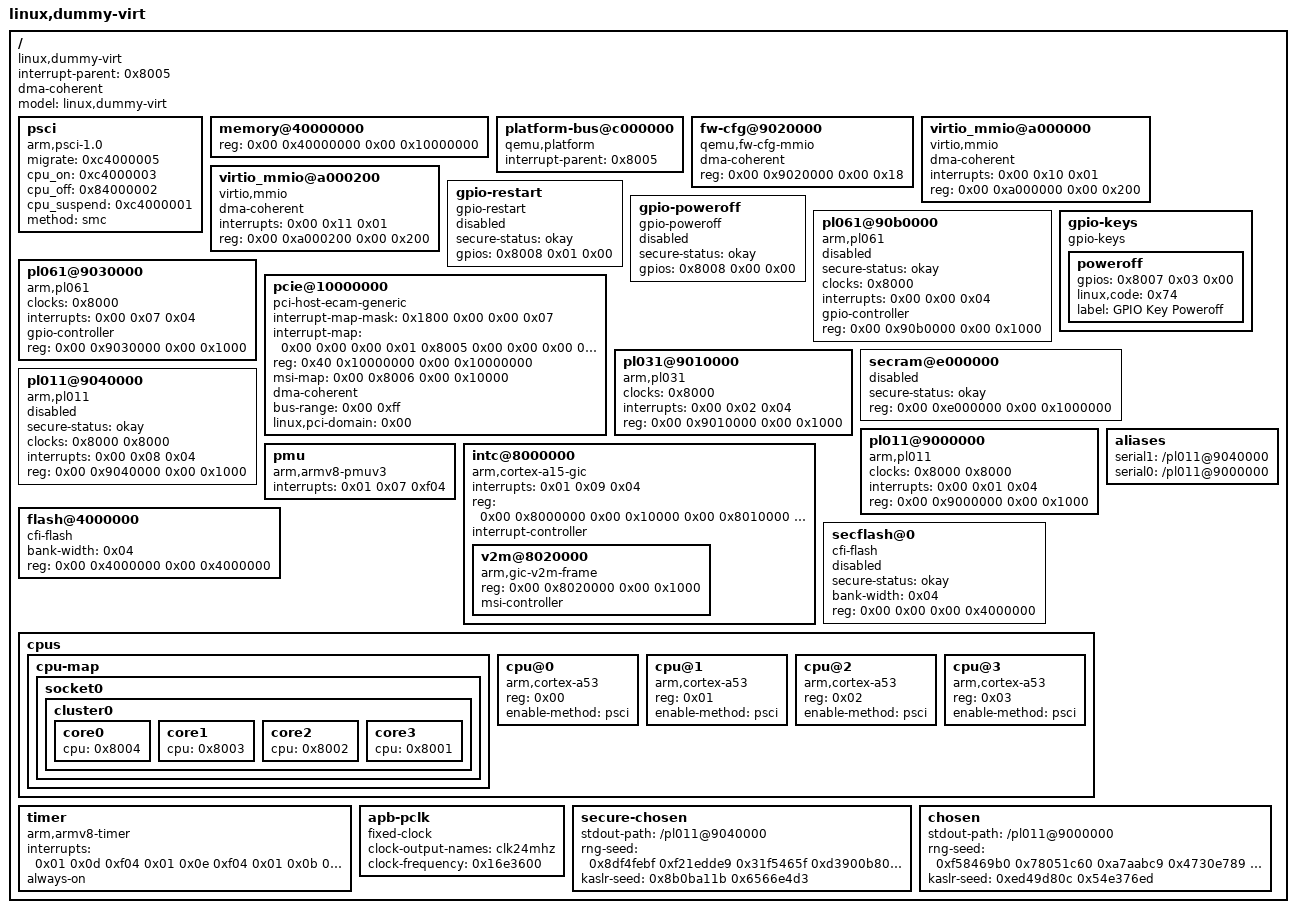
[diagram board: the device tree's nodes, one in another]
/dts-v1/;

/ {
	interrupt-parent = <0x8005>;
	dma-coherent;
	model = "linux,dummy-virt";
	#size-cells = <0x02>;
	#address-cells = <0x02>;
	compatible = "linux,dummy-virt";

	psci {
		migrate = <0xc4000005>;
		cpu_on = <0xc4000003>;
		cpu_off = <0x84000002>;
		cpu_suspend = <0xc4000001>;
		method = "smc";
		compatible = "arm,psci-1.0", "arm,psci-0.2", "arm,psci";
	};

	memory@40000000 {
		reg = <0x00 0x40000000 0x00 0x10000000>;
		device_type = "memory";
	};

    /* 没听懂 没用 */
	platform-bus@c000000 {
		interrupt-parent = <0x8005>;
		ranges = <0x00 0x00 0xc000000 0x2000000>;
		#address-cells = <0x01>;
		#size-cells = <0x01>;
		compatible = "qemu,platform", "simple-bus";
	};

    /* 估计那配置接口 只rtt */
	fw-cfg@9020000 {
		dma-coherent;
		reg = <0x00 0x9020000 0x00 0x18>;
		compatible = "qemu,fw-cfg-mmio";
	};

    /* 虚拟外设 */
	virtio_mmio@a000000 {
		dma-coherent;
		interrupts = <0x00 0x10 0x01>;
		reg = <0x00 0xa000000 0x00 0x200>;
		compatible = "virtio,mmio";
	};

	virtio_mmio@a000200 {
		dma-coherent;
		interrupts = <0x00 0x11 0x01>;
		reg = <0x00 0xa000200 0x00 0x200>;
		compatible = "virtio,mmio";
	};

    /* 系统重启 */
	gpio-restart {
		secure-status = "okay";
		status = "disabled";
		gpios = <0x8008 0x01 0x00>;
		compatible = "gpio-restart";
	};

    /* 系统关机 */
	gpio-poweroff {
		secure-status = "okay";
		status = "disabled";
		gpios = <0x8008 0x00 0x00>;
		compatible = "gpio-poweroff";
	};

    /* gpio控制器 只rtt */
	pl061@90b0000 {
		secure-status = "okay";
		status = "disabled";
		phandle = <0x8008>;
		clock-names = "apb_pclk";
		clocks = <0x8000>;
		interrupts = <0x00 0x00 0x04>;
		gpio-controller;
		#gpio-cells = <0x02>;
		compatible = "arm,pl061", "arm,primecell";
		reg = <0x00 0x90b0000 0x00 0x1000>;
	};


	gpio-keys {
		compatible = "gpio-keys";

		poweroff {
			gpios = <0x8007 0x03 0x00>;
			linux,code = <0x74>;
			label = "GPIO Key Poweroff";
		};
	};

	pl061@9030000 {
		phandle = <0x8007>;
		clock-names = "apb_pclk";
		clocks = <0x8000>;
		interrupts = <0x00 0x07 0x04>;
		gpio-controller;
		#gpio-cells = <0x02>;
		compatible = "arm,pl061", "arm,primecell";
		reg = <0x00 0x9030000 0x00 0x1000>;
	};

    /* 只rtt */
	pcie@10000000 {
		interrupt-map-mask = <0x1800 0x00 0x00 0x07>;
		interrupt-map = <0x00 0x00 0x00 0x01 0x8005 0x00 0x00 0x00 0x03 0x04 0x00 0x00 0x00 0x02 0x8005 0x00 0x00 0x00 0x04 0x04 0x00 0x00 0x00 0x03 0x8005 0x00 0x00 0x00 0x05 0x04 0x00 0x00 0x00 0x04 0x8005 0x00 0x00 0x00 0x06 0x04 0x800 0x00 0x00 0x01 0x8005 0x00 0x00 0x00 0x04 0x04 0x800 0x00 0x00 0x02 0x8005 0x00 0x00 0x00 0x05 0x04 0x800 0x00 0x00 0x03 0x8005 0x00 0x00 0x00 0x06 0x04 0x800 0x00 0x00 0x04 0x8005 0x00 0x00 0x00 0x03 0x04 0x1000 0x00 0x00 0x01 0x8005 0x00 0x00 0x00 0x05 0x04 0x1000 0x00 0x00 0x02 0x8005 0x00 0x00 0x00 0x06 0x04 0x1000 0x00 0x00 0x03 0x8005 0x00 0x00 0x00 0x03 0x04 0x1000 0x00 0x00 0x04 0x8005 0x00 0x00 0x00 0x04 0x04 0x1800 0x00 0x00 0x01 0x8005 0x00 0x00 0x00 0x06 0x04 0x1800 0x00 0x00 0x02 0x8005 0x00 0x00 0x00 0x03 0x04 0x1800 0x00 0x00 0x03 0x8005 0x00 0x00 0x00 0x04 0x04 0x1800 0x00 0x00 0x04 0x8005 0x00 0x00 0x00 0x05 0x04>;
		#interrupt-cells = <0x01>;
		ranges = <0x1000000 0x00 0x00 0x00 0x3eff0000 0x00 0x10000 0x2000000 0x00 0x10000000 0x00 0x10000000 0x00 0x2eff0000 0x3000000 0x80 0x00 0x80 0x00 0x80 0x00>;
		reg = <0x40 0x10000000 0x00 0x10000000>;
		msi-map = <0x00 0x8006 0x00 0x10000>;
		dma-coherent;
		bus-range = <0x00 0xff>;
		linux,pci-domain = <0x00>;
		#size-cells = <0x02>;
		#address-cells = <0x03>;
		device_type = "pci";
		compatible = "pci-host-ecam-generic";
	};

    /* rtc 只rtt */
	pl031@9010000 {
		clock-names = "apb_pclk";
		clocks = <0x8000>;
		interrupts = <0x00 0x02 0x04>;
		reg = <0x00 0x9010000 0x00 0x1000>;
		compatible = "arm,pl031", "arm,primecell";
	};

    /* trustzone sec world 专用内存 删除 */
	secram@e000000 {
		secure-status = "okay";
		status = "disabled";
		reg = <0x00 0xe000000 0x00 0x1000000>;
		device_type = "memory";
	};

	pl011@9040000 {
		secure-status = "okay";
		status = "disabled";
		clock-names = "uartclk", "apb_pclk";
		clocks = <0x8000 0x8000>;
		interrupts = <0x00 0x08 0x04>;
		reg = <0x00 0x9040000 0x00 0x1000>;
		compatible = "arm,pl011", "arm,primecell";
	};

	pl011@9000000 {
		clock-names = "uartclk", "apb_pclk";
		clocks = <0x8000 0x8000>;
		interrupts = <0x00 0x01 0x04>;
		reg = <0x00 0x9000000 0x00 0x1000>;
		compatible = "arm,pl011", "arm,primecell";
	};

    /* 不用 删除 */
	pmu {
		interrupts = <0x01 0x07 0xf04>;
		compatible = "arm,armv8-pmuv3";
	};

    /* 中断 */
	intc@8000000 {
		phandle = <0x8005>;
		interrupts = <0x01 0x09 0x04>;
		reg = <0x00 0x8000000 0x00 0x10000 0x00 0x8010000 0x00 0x10000 0x00 0x8030000 0x00 0x10000 0x00 0x8040000 0x00 0x10000>;
		compatible = "arm,cortex-a15-gic";
		ranges;
		#size-cells = <0x02>;
		#address-cells = <0x02>;
		interrupt-controller;
		#interrupt-cells = <0x03>;

        /* pcie用 linux删除 */
		v2m@8020000 {
			phandle = <0x8006>;
			reg = <0x00 0x8020000 0x00 0x1000>;
			msi-controller;
			compatible = "arm,gic-v2m-frame";
		};
	};

    /* 不用 删除 */
	flash@4000000 {
		bank-width = <0x04>;
		reg = <0x00 0x4000000 0x00 0x4000000>;
		compatible = "cfi-flash";
	};

	secflash@0 {
		secure-status = "okay";
		status = "disabled";
		bank-width = <0x04>;
		reg = <0x00 0x00 0x00 0x4000000>;
		compatible = "cfi-flash";
	};

	cpus {
		#size-cells = <0x00>;
		#address-cells = <0x01>;

		cpu-map {

			socket0 {

				cluster0 {

					core0 {
						cpu = <0x8004>;
					};

					core1 {
						cpu = <0x8003>;
					};

					core2 {
						cpu = <0x8002>;
					};

					core3 {
						cpu = <0x8001>;
					};
				};
			};
		};

		cpu@0 {
			phandle = <0x8004>;
			reg = <0x00>;
			enable-method = "psci";
			compatible = "arm,cortex-a53";
			device_type = "cpu";
		};

		cpu@1 {
			phandle = <0x8003>;
			reg = <0x01>;
			enable-method = "psci";
			compatible = "arm,cortex-a53";
			device_type = "cpu";
		};

		cpu@2 {
			phandle = <0x8002>;
			reg = <0x02>;
			enable-method = "psci";
			compatible = "arm,cortex-a53";
			device_type = "cpu";
		};

		cpu@3 {
			phandle = <0x8001>;
			reg = <0x03>;
			enable-method = "psci";
			compatible = "arm,cortex-a53";
			device_type = "cpu";
		};
	};

    /* PPI 都要 */
	timer {
        /* <type number flags> */
		interrupts = <0x01 0x0d 0xf04 0x01 0x0e 0xf04 0x01 0x0b 0xf04 0x01 0x0a 0xf04>;
		always-on;
		compatible = "arm,armv8-timer", "arm,armv7-timer";
	};

    /* apb外设时钟 */
	apb-pclk {
		phandle = <0x8000>;
		clock-output-names = "clk24mhz";
		clock-frequency = <0x16e3600>;
		#clock-cells = <0x00>;
		compatible = "fixed-clock";
	};

	aliases {
		serial1 = "/pl011@9040000";
		serial0 = "/pl011@9000000";
	};

	secure-chosen {
		stdout-path = "/pl011@9040000";
		rng-seed = <0x8df4febf 0xf21edde9 0x31f5465f 0xd3900b80 0xee84239a 0xdd7f3278 0x465115ed 0x769c471e>;
		kaslr-seed = <0x8b0ba11b 0x6566e4d3>;
	};

	chosen {
		stdout-path = "/pl011@9000000";
		rng-seed = <0xf58469b0 0x78051c60 0xa7aabc9 0x4730e789 0x75381635 0x63c71d74 0x4b7932ac 0x823e80ab>;
		kaslr-seed = <0xed49d80c 0x54e376ed>;
	};
};
